# R9A02G021 register map
Vendor: Renesas Electronics Corporation; Series: RISC-V; File version: 1.10.00 + 202304131714_CPU
CPU: other r0p0, little endian, no MPU, no FPU, VTOR, 4 interrupt priority bits, 32 interrupts
Registers are 8-bit, read-write, reset 0x0 unless marked. A register's access mark holds for its fields unless they carry their own. Offsets are from the block's base; [hi:lo] are bit positions; {n}, {i} and the like mark numbered series.

## ICU — ICU for CPU
Base 0x40006000
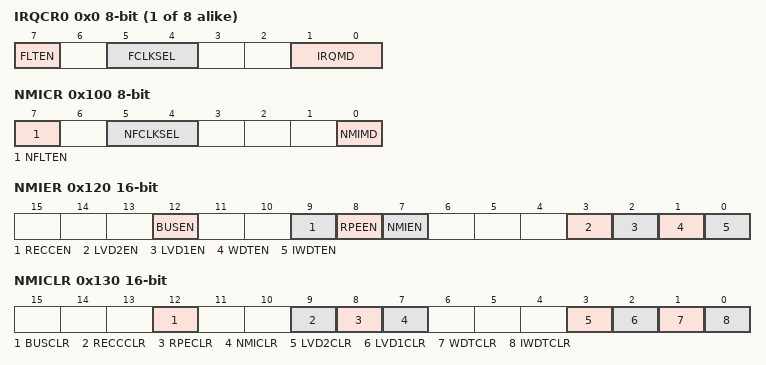
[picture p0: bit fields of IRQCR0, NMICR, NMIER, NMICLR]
{0x0+i} IRQCR{i} (i=0..7) — IRQ Control Register {i}
  [7] FLTEN — IRQi Digital Filter Enable
    0=Digital filter is disabled; 1=Digital filter is enabled
  [5:4] FCLKSEL — IRQi Digital Filter Sampling Clock Select
    0=PCLKB; 1=PCLKB/8; 2=PCLKB/32; 3=PCLKB/64
  [1:0] IRQMD — IRQi Detection Sense Select
    0=Falling edge; 1=Rising edge; 2=Rising and falling edges; 3=Low level
0x100 NMICR — NMI Pin Interrupt Control Register
  [7] NFLTEN — NMI Digital Filter Enable
    0=Disabled; 1=Enabled
  [5:4] NFCLKSEL — NMI Digital Filter Sampling Clock Select
    0=PCLKB; 1=PCLKB/8; 2=PCLKB/32; 3=PCLKB/64
  [0] NMIMD — NMI Detection Set
    0=Falling edge; 1=Rising edge
0x120 NMIER 16-bit — Non-Maskable Interrupt Enable Register
  [all] fields
    0=Disabled; 1=Enabled
  [12] BUSEN — Bus Error Interrupt Enable
  [9] RECCEN — SRAM ECC Error Interrupt Enable
  [8] RPEEN — SRAM Parity Error Interrupt Enable
  [7] NMIEN — NMI Pin Interrupt Enable
  [3] LVD2EN — Voltage monitor 2 Interrupt Enable
  [2] LVD1EN — Voltage monitor 1 Interrupt Enable
  [1] WDTEN — WDT Underflow/Refresh Error Interrupt Enable
  [0] IWDTEN — IWDT Underflow/Refresh Error Interrupt Enable
0x130 NMICLR 16-bit — Non-Maskable Interrupt Status Clear Register
  [12] BUSCLR — Bus Error Interrupt Status Flag Clear
    0=No effect; 1=Clear the NMISR.BUSST flag
  [9] RECCCLR — SRAM ECC Error Interrupt Status Flag Clear
    0=No effect; 1=Clear the NMISR.RECCST flag
  [8] RPECLR — SRAM Parity Error Interrupt Status Flag Clear
    0=No effect; 1=Clear the NMISR.RPEST flag
  [7] NMICLR — NMI Pin Interrupt Status Flag Clear
    0=No effect; 1=Clear the NMISR.NMIST flag
  [3] LVD2CLR — Voltage Monitor 2 Interrupt Status Flag Clear
    0=No effect; 1=Clear the NMISR.LVD2ST flag
  [2] LVD1CLR — Voltage Monitor 1 Interrupt Status Flag Clear
    0=No effect; 1=Clear the NMISR.LVD1ST flag
  [1] WDTCLR — WDT Underflow/Refresh Error Interrupt Status Flag Clear
    0=No effect; 1=Clear the NMISR.WDTST flag
  [0] IWDTCLR — IWDT Underflow/Refresh Error Interrupt Status Flag Clear
    0=No effect; 1=Clear the NMISR.IWDTST flag
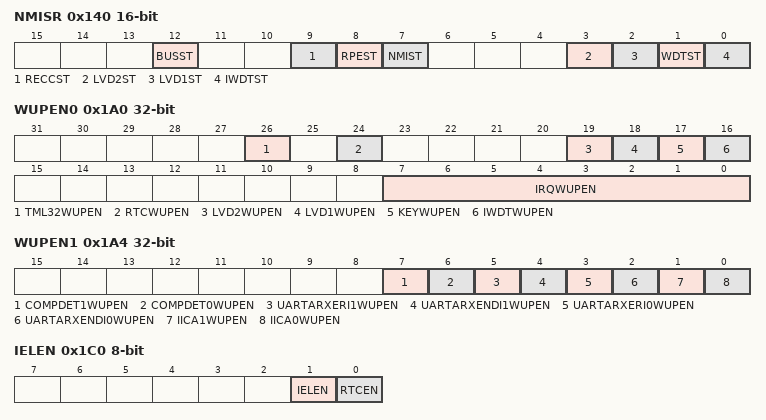
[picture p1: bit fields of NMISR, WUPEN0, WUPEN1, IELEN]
0x140 NMISR 16-bit ro — Non-Maskable Interrupt Status Register
  [all] fields
    0=Interrupt not requested; 1=Interrupt requested
  [12] BUSST — BUS Error Interrupt Status Flag
  [9] RECCST — SRAM ECC Error Interrupt Status Flag
  [8] RPEST — SRAM Parity Error Interrupt Status Flag
  [7] NMIST — NMI Pin Interrupt Status Flag
  [3] LVD2ST — Voltage Monitor 2 Interrupt Status Flag
  [2] LVD1ST — Voltage Monitor 1 Interrupt Status Flag
  [1] WDTST — WDT Underflow/Refresh Error Interrupt Status Flag
  [0] IWDTST — IWDT Underflow/Refresh Error Interrupt Status Flag
0x1A0 WUPEN0 32-bit — Wake Up Interrupt Enable Register 0
  [26] TML32WUPEN — TML32 Interrupt Software Standby/Snooze Mode Returns Enable
    0=Software Standby/Snooze Mode returns by TML32 interrupt disabled; 1=Software Standby/Snooze Mode returns by TML32 interrupt enabled
  [24] RTCWUPEN — RTC Interrupt Software Standby/Snooze Mode Returns Enable
    0=Software Standby/Snooze Mode returns by RTC interrupt disabled; 1=Software Standby/Snooze Mode returns by RTC interrupt enabled
  [19] LVD2WUPEN — LVD2 Interrupt Software Standby/Snooze Mode Returns Enable
    0=Software Standby/Snooze Mode returns by LVD2 interrupt disabled; 1=Software Standby/Snooze Mode returns by LVD2 interrupt enabled
  [18] LVD1WUPEN — LVD1 Interrupt Software Standby/Snooze Mode Returns Enable
    0=Software Standby/Snooze Mode returns by LVD1 interrupt disabled; 1=Software Standby/Snooze Mode returns by LVD1 interrupt enabled
  [17] KEYWUPEN — Key Interrupt Software Standby/Snooze Mode Returns Enable
    0=Software Standby/Snooze Mode returns by Key interrupt disabled; 1=Software Standby/Snooze Mode returns by Key interrupt enabled
  [16] IWDTWUPEN — IWDT Interrupt Software Standby/Snooze Mode Returns Enable
    0=Software Standby/Snooze Mode returns by IWDT interrupt disabled; 1=Software Standby/Snooze Mode returns by IWDT interrupt enabled
  [7:0] IRQWUPEN — IRQn (n = 0 to 7) Interrupt Software Standby/Snooze Mode Returns Enable, whereas IRQn corresponds to IRQWUPEN[n]
    0=Software Standby/Snooze Mode returns by IRQn interrupt disabled; 1=Software Standby/Snooze Mode returns by IRQn interrupt enabled
0x1A4 WUPEN1 32-bit — Wake Up Interrupt Enable Register 1
  [7] COMPDET1WUPEN — COMP_DET1 Interrupt Software Standby/Snooze Mode Returns Enable
    0=Software standby/Snooze mode returns by COMP_DET1 interrupt disabled; 1=Software standby/Snooze mode returns by COMP_DET1 interrupt enabled
  [6] COMPDET0WUPEN — COMP_DET0 Interrupt Software Standby/Snooze Mode Returns Enable
    0=Software standby/Snooze mode returns by COMP_DET0 interrupt disabled; 1=Software standby/Snooze mode returns by COMP_DET0 interrupt enabled
  [5] UARTARXERI1WUPEN — UARTA_RX_ERI1 Interrupt Software Standby/Snooze Mode Returns Enable
    0=Software standby/Snooze mode returns by UARTA_RX_ERI1 interrupt disabled; 1=Software standby/Snooze mode returns by UARTA_RX_ERI1 interrupt enabled
  [4] UARTARXENDI1WUPEN — UARTA_RX_ENDI1 Interrupt Software Standby/Snooze Mode Returns Enable
    0=Software standby/Snooze mode returns by UARTA_RX_ENDI1 interrupt disabled; 1=Software standby/Snooze mode returns by UARTA_RX_ENDI1 interrupt enabled
  [3] UARTARXERI0WUPEN — UARTA_RX_ERI0 Interrupt Software Standby/Snooze Mode Returns Enable
    0=Software standby/Snooze mode returns by UARTA_RX_ERI0 interrupt disabled; 1=Software standby/Snooze mode returns by UARTA_RX_ERI0 interrupt enabled
  [2] UARTARXENDI0WUPEN — UARTA_RX_ENDI0 Interrupt Software Standby/Snooze Mode Returns Enable
    0=Software standby/Snooze mode returns by UARTA_RX_ENDI0 interrupt disabled; 1=Software standby/Snooze mode returns by UARTA_RX_ENDI0 interrupt enabled
  [1] IICA1WUPEN — IIC1_ENDI/IIC1_WUI Interrupt Software Standby/Snooze Mode Returns Enable
    0=Software Standby/Snooze mode returns by IIC1_ENDI/IIC1_WUI interrupt disabled; 1=Software Standby/Snooze mode returns by IIC1_ENDI/IIC1_WUI interrupt enabled
  [0] IICA0WUPEN — IIC0_ENDI/IIC0_WUI Interrupt Software Standby/Snooze Mode Returns Enable
    0=Software Standby/Snooze mode returns by IIC0_ENDI/IIC0_WUI interrupt disabled; 1=Software Standby/Snooze mode returns by IIC0_ENDI/IIC0_WUI interrupt enabled
0x1C0 IELEN — ICU Event Enable Register
  [1] IELEN — Parts Asynchronous Interrupts Enable (when LPOPTEN bit = 1)
    0=Disabled; 1=Enabled
  [0] RTCEN — RTC Interrupt Enable (when LPOPT.LPOPTEN bit = 1)
    0=Disabled; 1=Enabled
0x200 SELSR0 16-bit — SYS Event Link Setting Register
{0x300+4i} IELSR{i} (i=0..31) 32-bit — ICU Event Link Setting Register {i}
